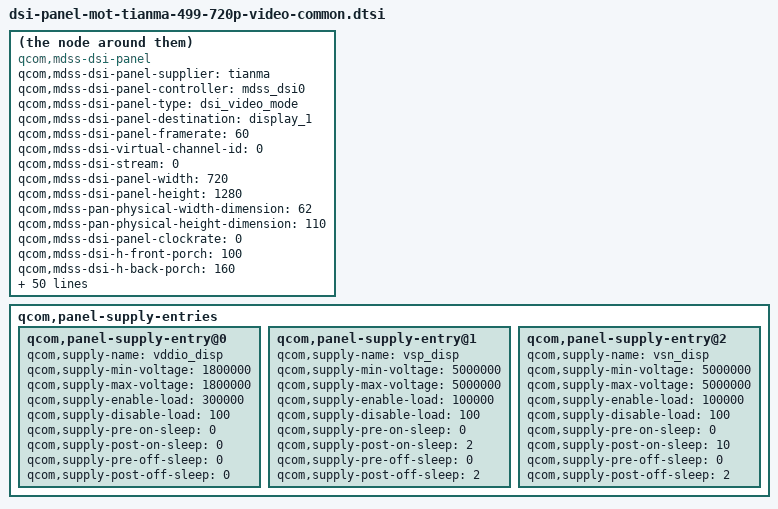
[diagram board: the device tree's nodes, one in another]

compatible = "qcom,mdss-dsi-panel";
qcom,mdss-dsi-panel-supplier = "tianma";
qcom,mdss-dsi-panel-controller = <&mdss_dsi0>;
qcom,mdss-dsi-panel-type = "dsi_video_mode";
qcom,mdss-dsi-panel-destination = "display_1";
qcom,mdss-dsi-panel-framerate = <60>;
qcom,mdss-dsi-virtual-channel-id = <0>;
qcom,mdss-dsi-stream = <0>;
qcom,mdss-dsi-panel-width = <720>;
qcom,mdss-dsi-panel-height = <1280>;
qcom,mdss-pan-physical-width-dimension = <62>;
qcom,mdss-pan-physical-height-dimension = <110>;

qcom,mdss-dsi-panel-clockrate = <0>;
qcom,mdss-dsi-h-front-porch = <100>;
qcom,mdss-dsi-h-back-porch = <160>;
qcom,mdss-dsi-h-pulse-width = <20>;
qcom,mdss-dsi-h-sync-skew = <0>;
qcom,mdss-dsi-v-back-porch = <20>;
qcom,mdss-dsi-v-front-porch = <40>;
qcom,mdss-dsi-v-pulse-width = <8>;
qcom,mdss-dsi-h-left-border = <0>;
qcom,mdss-dsi-h-right-border = <0>;
qcom,mdss-dsi-v-top-border = <0>;
qcom,mdss-dsi-v-bottom-border = <0>;
qcom,mdss-dsi-bpp = <24>;
qcom,mdss-dsi-underflow-color = <0xff>;
qcom,mdss-dsi-border-color = <0>;

qcom,mdss-dsi-reset-sequence = <1 1>, <0 10>, <1 20>;
qcom,mdss-dsi-dis-reset-sequence = <1 10>, <0 0>;

qcom,mdss-dsi-on-command = [
	39 01 00 00 00 00 04 FF 98 81 03
	15 01 00 00 00 00 02 01 00
	15 01 00 00 00 00 02 02 00
	15 01 00 00 00 00 02 03 73
	15 01 00 00 00 00 02 04 D3
	15 01 00 00 00 00 02 05 00
	15 01 00 00 00 00 02 06 0A
	15 01 00 00 00 00 02 07 0E
	15 01 00 00 00 00 02 08 00
	15 01 00 00 00 00 02 09 01
	15 01 00 00 00 00 02 0a 01
	15 01 00 00 00 00 02 0b 01
	15 01 00 00 00 00 02 0c 01
	15 01 00 00 00 00 02 0d 01
	15 01 00 00 00 00 02 0e 01
	15 01 00 00 00 00 02 0f 15
	15 01 00 00 00 00 02 10 15
	15 01 00 00 00 00 02 11 00
	15 01 00 00 00 00 02 12 00
	15 01 00 00 00 00 02 13 00
	15 01 00 00 00 00 02 14 00
	15 01 00 00 00 00 02 15 00
	15 01 00 00 00 00 02 16 00
	15 01 00 00 00 00 02 17 00
	15 01 00 00 00 00 02 18 00
	15 01 00 00 00 00 02 19 00
	15 01 00 00 00 00 02 1a 00
	15 01 00 00 00 00 02 1b 00
	15 01 00 00 00 00 02 1c 00
	15 01 00 00 00 00 02 1d 00
	15 01 00 00 00 00 02 1e 40
	15 01 00 00 00 00 02 1f 80
	15 01 00 00 00 00 02 20 06
	15 01 00 00 00 00 02 21 01
	15 01 00 00 00 00 02 22 00
	15 01 00 00 00 00 02 23 00
	15 01 00 00 00 00 02 24 00
	15 01 00 00 00 00 02 25 00
	15 01 00 00 00 00 02 26 00
	15 01 00 00 00 00 02 27 00
	15 01 00 00 00 00 02 28 33
	15 01 00 00 00 00 02 29 03
	15 01 00 00 00 00 02 2a 00
	15 01 00 00 00 00 02 2b 00
	15 01 00 00 00 00 02 2c 00
	15 01 00 00 00 00 02 2d 00
	15 01 00 00 00 00 02 2e 00
	15 01 00 00 00 00 02 2f 00
	15 01 00 00 00 00 02 30 00
	15 01 00 00 00 00 02 31 00
	15 01 00 00 00 00 02 32 00
	15 01 00 00 00 00 02 33 00
	15 01 00 00 00 00 02 34 03
	15 01 00 00 00 00 02 35 00
	15 01 00 00 00 00 02 36 03
	15 01 00 00 00 00 02 37 00
	15 01 00 00 00 00 02 38 00
	15 01 00 00 00 00 02 39 00
	15 01 00 00 00 00 02 3a 40
	15 01 00 00 00 00 02 3b 40
	15 01 00 00 00 00 02 3c 00
	15 01 00 00 00 00 02 3d 00
	15 01 00 00 00 00 02 3e 00
	15 01 00 00 00 00 02 3f 00
	15 01 00 00 00 00 02 40 00
	15 01 00 00 00 00 02 41 00
	15 01 00 00 00 00 02 42 00
	15 01 00 00 00 00 02 43 00
	15 01 00 00 00 00 02 44 00
	15 01 00 00 00 00 02 50 01
	15 01 00 00 00 00 02 51 23
	15 01 00 00 00 00 02 52 45
	15 01 00 00 00 00 02 53 67
	15 01 00 00 00 00 02 54 89
	15 01 00 00 00 00 02 55 ab
	15 01 00 00 00 00 02 56 01
	15 01 00 00 00 00 02 57 23
	15 01 00 00 00 00 02 58 45
	15 01 00 00 00 00 02 59 67
	15 01 00 00 00 00 02 5a 89
	15 01 00 00 00 00 02 5b ab
	15 01 00 00 00 00 02 5c cd
	15 01 00 00 00 00 02 5d ef
	15 01 00 00 00 00 02 5e 11
	15 01 00 00 00 00 02 5f 0D
	15 01 00 00 00 00 02 60 0C
	15 01 00 00 00 00 02 61 0F
	15 01 00 00 00 00 02 62 0E
	15 01 00 00 00 00 02 63 06
	15 01 00 00 00 00 02 64 07
	15 01 00 00 00 00 02 65 02
	15 01 00 00 00 00 02 66 02
	15 01 00 00 00 00 02 67 02
	15 01 00 00 00 00 02 68 02
	15 01 00 00 00 00 02 69 02
	15 01 00 00 00 00 02 6a 02
	15 01 00 00 00 00 02 6b 02
	15 01 00 00 00 00 02 6c 02
	15 01 00 00 00 00 02 6d 02
	15 01 00 00 00 00 02 6e 02
	15 01 00 00 00 00 02 6f 02
	15 01 00 00 00 00 02 70 02
	15 01 00 00 00 00 02 71 02
	15 01 00 00 00 00 02 72 08
	15 01 00 00 00 00 02 73 00
	15 01 00 00 00 00 02 74 01
	15 01 00 00 00 00 02 75 0D
	15 01 00 00 00 00 02 76 0C
	15 01 00 00 00 00 02 77 0F
	15 01 00 00 00 00 02 78 0E
	15 01 00 00 00 00 02 79 06
	15 01 00 00 00 00 02 7a 07
	15 01 00 00 00 00 02 7b 02
	15 01 00 00 00 00 02 7c 02
	15 01 00 00 00 00 02 7d 02
	15 01 00 00 00 00 02 7e 02
	15 01 00 00 00 00 02 7f 02
	15 01 00 00 00 00 02 80 02
	15 01 00 00 00 00 02 81 02
	15 01 00 00 00 00 02 82 02
	15 01 00 00 00 00 02 83 02
	15 01 00 00 00 00 02 84 02
	15 01 00 00 00 00 02 85 02
	15 01 00 00 00 00 02 86 02
	15 01 00 00 00 00 02 87 02
	15 01 00 00 00 00 02 88 08
	15 01 00 00 00 00 02 89 00
	15 01 00 00 00 00 02 8A 01

	39 01 00 00 00 00 04 FF 98 81 04
	15 01 00 00 00 00 02 6C 15
	15 01 00 00 00 00 02 6E 3B
	15 01 00 00 00 00 02 6F 37
	15 01 00 00 00 00 02 8D 14
	15 01 00 00 00 00 02 3A A4
	15 01 00 00 00 00 02 87 BA
	15 01 00 00 00 00 02 26 76
	15 01 00 00 00 00 02 B2 D1
	15 01 00 00 00 00 02 B5 06
	15 01 00 00 00 00 02 31 75

	39 01 00 00 00 00 04 FF 98 81 01
	15 01 00 00 00 00 02 22 09
	15 01 00 00 00 00 02 31 00
	15 01 00 00 00 00 02 50 8D
	15 01 00 00 00 00 02 51 98
	15 01 00 00 00 00 02 53 6F
	15 01 00 00 00 00 02 55 7A
	15 01 00 00 00 00 02 60 1F
	15 01 00 00 00 00 02 A0 1D
	15 01 00 00 00 00 02 A1 30
	15 01 00 00 00 00 02 A2 3C
	15 01 00 00 00 00 02 A3 13
	15 01 00 00 00 00 02 A4 15
	15 01 00 00 00 00 02 A5 28
	15 01 00 00 00 00 02 A6 1B
	15 01 00 00 00 00 02 A7 1E
	15 01 00 00 00 00 02 A8 A1
	15 01 00 00 00 00 02 A9 1B
	15 01 00 00 00 00 02 AA 29
	15 01 00 00 00 00 02 AB 8A
	15 01 00 00 00 00 02 AC 1E
	15 01 00 00 00 00 02 AD 1F
	15 01 00 00 00 00 02 AE 53
	15 01 00 00 00 00 02 AF 27
	15 01 00 00 00 00 02 B0 2C
	15 01 00 00 00 00 02 B1 4C
	15 01 00 00 00 00 02 B2 56
	15 01 00 00 00 00 02 B3 1D

	15 01 00 00 00 00 02 C0 1D
	15 01 00 00 00 00 02 C1 30
	15 01 00 00 00 00 02 C2 3C
	15 01 00 00 00 00 02 C3 13
	15 01 00 00 00 00 02 C4 15
	15 01 00 00 00 00 02 C5 28
	15 01 00 00 00 00 02 C6 1B
	15 01 00 00 00 00 02 C7 1E
	15 01 00 00 00 00 02 C8 A1
	15 01 00 00 00 00 02 C9 1B
	15 01 00 00 00 00 02 CA 29
	15 01 00 00 00 00 02 CB 8A
	15 01 00 00 00 00 02 CC 1E
	15 01 00 00 00 00 02 CD 1F
	15 01 00 00 00 00 02 CE 53
	15 01 00 00 00 00 02 CF 27
	15 01 00 00 00 00 02 D0 2C
	15 01 00 00 00 00 02 D1 4C
	15 01 00 00 00 00 02 D2 56
	15 01 00 00 00 00 02 D3 1D

	39 01 00 00 00 00 04 FF 98 81 00
	39 01 00 00 00 00 03 51 00 00
	15 01 00 00 00 00 02 53 2C
	15 01 00 00 00 00 02 55 00
	15 01 00 00 00 00 02 68 05
	05 01 00 00 78 00 01 11
	05 01 00 00 14 00 01 29];		/* Display on */

qcom,mdss-dsi-off-command = [
	05 01 00 00 14 00 01 28
	05 01 00 00 78 00 01 10];

qcom,mdss-dsi-on-command-state = "dsi_lp_mode";
qcom,mdss-dsi-off-command-state = "dsi_lp_mode";

qcom,mdss-dsi-h-sync-pulse = <1>;
qcom,mdss-dsi-traffic-mode = "burst_mode";
qcom,mdss-dsi-bllp-eof-power-mode;
qcom,mdss-dsi-bllp-power-mode;
qcom,mdss-dsi-lp11-init;
qcom,mdss-dsi-tx-eot-append;
qcom,mdss-dsi-dma-trigger = "trigger_sw";
qcom,mdss-dsi-mdp-trigger = "none";
qcom,mdss-dsi-lane-0-state;
qcom,mdss-dsi-lane-1-state;
qcom,mdss-dsi-lane-2-state;
qcom,mdss-dsi-lane-3-state;

qcom,mdss-dsi-panel-timings = [C3 1E 14 00 44 48 18 90 19 03 04 00];
qcom,mdss-dsi-t-clk-post = <0x04>;
qcom,mdss-dsi-t-clk-pre = <0x23>;

qcom,mdss-dsi-bl-min-level = <1>;
qcom,mdss-dsi-bl-max-level = <4095>;
qcom,mdss-dsi-bl-pmic-control-type = "bl_ctrl_dcs";
qcom,bklt-dcs-12bits-enabled;

qcom,cont-splash-enabled;
qcom,esd-check-enabled;
qcom,mdss-dsi-panel-status-check-mode = "reg_read";
qcom,mdss-dsi-panel-status-command = [06 01 00 01 00 00 01 0A];
qcom,mdss-dsi-panel-status-command-state = "dsi_hs_mode";
qcom,mdss-dsi-panel-status-value = <0x9C>;

qcom,panel-supply-entries {
	#address-cells = <1>;
	#size-cells = <0>;
	qcom,panel-supply-entry@0 {
		qcom,supply-name = "vddio_disp";
		qcom,supply-min-voltage = <1800000>;
		qcom,supply-max-voltage = <1800000>;
		qcom,supply-enable-load = <300000>;
		qcom,supply-disable-load = <100>;
		qcom,supply-pre-on-sleep = <0>;
		qcom,supply-post-on-sleep = <0>;
		qcom,supply-pre-off-sleep = <0>;
		qcom,supply-post-off-sleep = <0>;
	};
        qcom,panel-supply-entry@1 {
		qcom,supply-name = "vsp_disp";
		qcom,supply-min-voltage = <5000000>;
		qcom,supply-max-voltage = <5000000>;
		qcom,supply-enable-load = <100000>;
		qcom,supply-disable-load = <100>;
		qcom,supply-pre-on-sleep = <0>;
		qcom,supply-post-on-sleep = <2>;
		qcom,supply-pre-off-sleep = <0>;
		qcom,supply-post-off-sleep = <2>;
	};
	qcom,panel-supply-entry@2 {
		qcom,supply-name = "vsn_disp";
		qcom,supply-min-voltage = <5000000>;
		qcom,supply-max-voltage = <5000000>;
		qcom,supply-enable-load = <100000>;
		qcom,supply-disable-load = <100>;
		qcom,supply-pre-on-sleep = <0>;
		qcom,supply-post-on-sleep = <10>;
		qcom,supply-pre-off-sleep = <0>;
		qcom,supply-post-off-sleep = <2>;
	};
};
